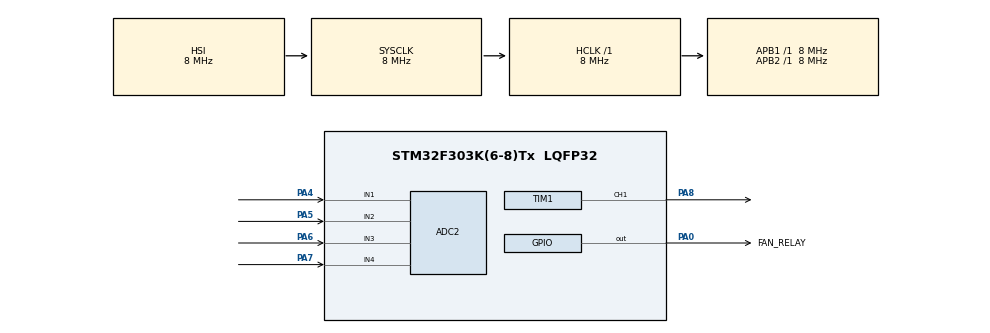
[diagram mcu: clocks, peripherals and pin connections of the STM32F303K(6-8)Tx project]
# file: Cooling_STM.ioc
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ADC2.Channel-0\#ChannelRegularConversion=ADC_CHANNEL_1
ADC2.Channel-1\#ChannelRegularConversion=ADC_CHANNEL_2
ADC2.Channel-2\#ChannelRegularConversion=ADC_CHANNEL_3
ADC2.Channel-3\#ChannelRegularConversion=ADC_CHANNEL_4
ADC2.NbrOfConversion=4
ADC2.NbrOfConversionFlag=1
ADC2.Offset-0\#ChannelRegularConversion=0
ADC2.Offset-1\#ChannelRegularConversion=0
ADC2.Offset-2\#ChannelRegularConversion=0
ADC2.Offset-3\#ChannelRegularConversion=0
ADC2.OffsetNumber-0\#ChannelRegularConversion=ADC_OFFSET_NONE
ADC2.OffsetNumber-1\#ChannelRegularConversion=ADC_OFFSET_NONE
ADC2.OffsetNumber-2\#ChannelRegularConversion=ADC_OFFSET_NONE
ADC2.OffsetNumber-3\#ChannelRegularConversion=ADC_OFFSET_NONE
ADC2.Rank-0\#ChannelRegularConversion=1
ADC2.Rank-1\#ChannelRegularConversion=2
ADC2.Rank-2\#ChannelRegularConversion=3
ADC2.Rank-3\#ChannelRegularConversion=4
ADC2.SamplingTime-0\#ChannelRegularConversion=ADC_SAMPLETIME_1CYCLE_5
ADC2.SamplingTime-1\#ChannelRegularConversion=ADC_SAMPLETIME_1CYCLE_5
ADC2.SamplingTime-2\#ChannelRegularConversion=ADC_SAMPLETIME_1CYCLE_5
ADC2.SamplingTime-3\#ChannelRegularConversion=ADC_SAMPLETIME_1CYCLE_5
ADC2.SamplingTimeOPAMP-1\#ChannelRegularConversion=ADC_SAMPLETIME_4CYCLES_5
ADC2.SamplingTimeOPAMP-2\#ChannelRegularConversion=ADC_SAMPLETIME_4CYCLES_5
ADC2.SamplingTimeOPAMP-3\#ChannelRegularConversion=ADC_SAMPLETIME_4CYCLES_5
Mcu.Family=STM32F3
Mcu.Name=STM32F303K(6-8)Tx
Mcu.Package=LQFP32
NVIC.PriorityGroup=NVIC_PRIORITYGROUP_4
PA0.GPIO_Label=FAN_RELAY
PA0.Signal=GPIO_Output
PA4.Mode=IN1-Single-Ended
PA4.Signal=ADC2_IN1
PA5.Mode=IN2-Single-Ended
PA5.Signal=ADC2_IN2
PA6.Mode=IN3-Single-Ended
PA6.Signal=ADC2_IN3
PA7.Mode=IN4-Single-Ended
PA7.Signal=ADC2_IN4
PA8.Signal=S_TIM1_CH1
ProjectManager.HeapSize=0x200
ProjectManager.StackSize=0x400
ProjectManager.TargetToolchain=STM32CubeIDE
RCC.AHBFreq_Value=8000000
RCC.APB1Freq_Value=8000000
RCC.APB2Freq_Value=8000000
RCC.CortexFreq_Value=8000000
RCC.HSE_VALUE=8000000
RCC.HSI_VALUE=8000000
RCC.PLLMUL=RCC_PLL_MUL4
RCC.SYSCLKFreq_VALUE=8000000
SH.S_TIM1_CH1.0=TIM1_CH1,PWM Generation1 CH1
TIM1.Channel-PWM\ Generation1\ CH1=TIM_CHANNEL_1
TIM1.Period=99
TIM1.Prescaler=79
TIM1.Pulse-PWM\ Generation1\ CH1=50
board=custom

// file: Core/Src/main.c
/* USER CODE BEGIN Header */
/**
  ******************************************************************************
  * @file           : main.c
  * @brief          : Main program body
  ******************************************************************************
  * @attention
  *
  * Copyright (c) 2026 STMicroelectronics.
  * All rights reserved.
  *
  * This software is licensed under terms that can be found in the LICENSE file
  * in the root directory of this software component.
  * If no LICENSE file comes with this software, it is provided AS-IS.
  *
  ******************************************************************************
  */
/* USER CODE END Header */
#include "main.h"

ADC_HandleTypeDef hadc2;

TIM_HandleTypeDef htim1;

void SystemClock_Config(void);
static void MX_GPIO_Init(void);
static void MX_ADC2_Init(void);
static void MX_TIM1_Init(void);

void Pump_SetDutyPercent(uint8_t percent)
{
    if (percent > 100) percent = 100;

    uint32_t period = __HAL_TIM_GET_AUTORELOAD(&htim1);
    uint32_t pulse = (period + 1) * percent / 100;

    __HAL_TIM_SET_COMPARE(&htim1, TIM_CHANNEL_1, pulse);
}

int main(void)
{

  /* MCU Configuration--------------------------------------------------------*/

  /* Reset of all peripherals, Initializes the Flash interface and the Systick. */
  HAL_Init();

  /* Configure the system clock */
  SystemClock_Config();

  /* Initialize all configured peripherals */
  MX_GPIO_Init();
  MX_ADC2_Init();
  MX_TIM1_Init();
  /* USER CODE BEGIN 2 */
  HAL_TIM_PWM_Start(&htim1, TIM_CHANNEL_1);
  __HAL_TIM_SET_COMPARE(&htim1, TIM_CHANNEL_1, (htim1.Init.Period + 1)/2); // for 50% duty

  /* USER CODE END 2 */

  /* Infinite loop */
  /* USER CODE BEGIN WHILE */
  while (1)
  {
	  HAL_ADC_Start(&hadc2);

	  // read temp1
	  HAL_ADC_PollForConversion(&hadc2, 100);
	  uint32_t adc_temp1 = HAL_ADC_GetValue(&hadc2);

	  // read temp2
	  HAL_ADC_PollForConversion(&hadc2, 100);
	  uint32_t adc_temp2 = HAL_ADC_GetValue(&hadc2);

	  // read pressure1
	  HAL_ADC_PollForConversion(&hadc2, 100);
	  uint32_t adc_press1 = HAL_ADC_GetValue(&hadc2);

	  // read pressure2
	  HAL_ADC_PollForConversion(&hadc2, 100);
	  uint32_t adc_press2 = HAL_ADC_GetValue(&hadc2);

	  HAL_ADC_Stop(&hadc2);

	  // TODO: replace after measuring real 70°F value
	  #define TEMP_ADC_THRESHOLD_70F 2000

	  uint8_t fan_on =
	      (adc_temp1 > TEMP_ADC_THRESHOLD_70F) ||
	      (adc_temp2 > TEMP_ADC_THRESHOLD_70F);

	  HAL_GPIO_WritePin(
	      FAN_RELAY_GPIO_Port,
	      FAN_RELAY_Pin,
	      fan_on ? GPIO_PIN_SET : GPIO_PIN_RESET
	  );

	  // pump fixed at 50%
	  Pump_SetDutyPercent(50);

	  HAL_Delay(250);
  }
  /* USER CODE END 3 */
}

void SystemClock_Config(void)
{
  RCC_OscInitTypeDef RCC_OscInitStruct = {0};
  RCC_ClkInitTypeDef RCC_ClkInitStruct = {0};
  RCC_PeriphCLKInitTypeDef PeriphClkInit = {0};

  /** Initializes the RCC Oscillators according to the specified parameters
  * in the RCC_OscInitTypeDef structure.
  */
  RCC_OscInitStruct.OscillatorType = RCC_OSCILLATORTYPE_HSI;
  RCC_OscInitStruct.HSIState = RCC_HSI_ON;
  RCC_OscInitStruct.HSICalibrationValue = RCC_HSICALIBRATION_DEFAULT;
  RCC_OscInitStruct.PLL.PLLState = RCC_PLL_ON;
  RCC_OscInitStruct.PLL.PLLSource = RCC_PLLSOURCE_HSI;
  RCC_OscInitStruct.PLL.PLLMUL = RCC_PLL_MUL4;
  if (HAL_RCC_OscConfig(&RCC_OscInitStruct) != HAL_OK)
  {
    Error_Handler();
  }

  /** Initializes the CPU, AHB and APB buses clocks
  */
  RCC_ClkInitStruct.ClockType = RCC_CLOCKTYPE_HCLK|RCC_CLOCKTYPE_SYSCLK
                              |RCC_CLOCKTYPE_PCLK1|RCC_CLOCKTYPE_PCLK2;
  RCC_ClkInitStruct.SYSCLKSource = RCC_SYSCLKSOURCE_HSI;
  RCC_ClkInitStruct.AHBCLKDivider = RCC_SYSCLK_DIV1;
  RCC_ClkInitStruct.APB1CLKDivider = RCC_HCLK_DIV1;
  RCC_ClkInitStruct.APB2CLKDivider = RCC_HCLK_DIV1;

  if (HAL_RCC_ClockConfig(&RCC_ClkInitStruct, FLASH_LATENCY_0) != HAL_OK)
  {
    Error_Handler();
  }
  PeriphClkInit.PeriphClockSelection = RCC_PERIPHCLK_TIM1|RCC_PERIPHCLK_ADC12;
  PeriphClkInit.Adc12ClockSelection = RCC_ADC12PLLCLK_DIV1;
  PeriphClkInit.Tim1ClockSelection = RCC_TIM1CLK_HCLK;
  if (HAL_RCCEx_PeriphCLKConfig(&PeriphClkInit) != HAL_OK)
  {
    Error_Handler();
  }
}

static void MX_ADC2_Init(void)
{

  ADC_ChannelConfTypeDef sConfig = {0};

  /** Common config
  */
  hadc2.Instance = ADC2;
  hadc2.Init.ClockPrescaler = ADC_CLOCK_ASYNC_DIV1;
  hadc2.Init.Resolution = ADC_RESOLUTION_12B;
  hadc2.Init.ScanConvMode = ADC_SCAN_ENABLE;
  hadc2.Init.ContinuousConvMode = DISABLE;
  hadc2.Init.DiscontinuousConvMode = DISABLE;
  hadc2.Init.ExternalTrigConvEdge = ADC_EXTERNALTRIGCONVEDGE_NONE;
  hadc2.Init.ExternalTrigConv = ADC_SOFTWARE_START;
  hadc2.Init.DataAlign = ADC_DATAALIGN_RIGHT;
  hadc2.Init.NbrOfConversion = 4;
  hadc2.Init.DMAContinuousRequests = DISABLE;
  hadc2.Init.EOCSelection = ADC_EOC_SINGLE_CONV;
  hadc2.Init.LowPowerAutoWait = DISABLE;
  hadc2.Init.Overrun = ADC_OVR_DATA_OVERWRITTEN;
  if (HAL_ADC_Init(&hadc2) != HAL_OK)
  {
    Error_Handler();
  }

  /** Configure Regular Channel
  */
  sConfig.Channel = ADC_CHANNEL_1;
  sConfig.Rank = ADC_REGULAR_RANK_1;
  sConfig.SingleDiff = ADC_SINGLE_ENDED;
  sConfig.SamplingTime = ADC_SAMPLETIME_1CYCLE_5;
  sConfig.OffsetNumber = ADC_OFFSET_NONE;
  sConfig.Offset = 0;
  if (HAL_ADC_ConfigChannel(&hadc2, &sConfig) != HAL_OK)
  {
    Error_Handler();
  }

  /** Configure Regular Channel
  */
  sConfig.Channel = ADC_CHANNEL_2;
  sConfig.Rank = ADC_REGULAR_RANK_2;
  if (HAL_ADC_ConfigChannel(&hadc2, &sConfig) != HAL_OK)
  {
    Error_Handler();
  }

  /** Configure Regular Channel
  */
  sConfig.Channel = ADC_CHANNEL_3;
  sConfig.Rank = ADC_REGULAR_RANK_3;
  if (HAL_ADC_ConfigChannel(&hadc2, &sConfig) != HAL_OK)
  {
    Error_Handler();
  }

  /** Configure Regular Channel
  */
  sConfig.Channel = ADC_CHANNEL_4;
  sConfig.Rank = ADC_REGULAR_RANK_4;
  if (HAL_ADC_ConfigChannel(&hadc2, &sConfig) != HAL_OK)
  {
    Error_Handler();
  }

}

static void MX_TIM1_Init(void)
{

  TIM_MasterConfigTypeDef sMasterConfig = {0};
  TIM_OC_InitTypeDef sConfigOC = {0};
  TIM_BreakDeadTimeConfigTypeDef sBreakDeadTimeConfig = {0};

  htim1.Instance = TIM1;
  htim1.Init.Prescaler = 79;
  htim1.Init.CounterMode = TIM_COUNTERMODE_UP;
  htim1.Init.Period = 99;
  htim1.Init.ClockDivision = TIM_CLOCKDIVISION_DIV1;
  htim1.Init.RepetitionCounter = 0;
  htim1.Init.AutoReloadPreload = TIM_AUTORELOAD_PRELOAD_DISABLE;
  if (HAL_TIM_PWM_Init(&htim1) != HAL_OK)
  {
    Error_Handler();
  }
  sMasterConfig.MasterOutputTrigger = TIM_TRGO_RESET;
  sMasterConfig.MasterOutputTrigger2 = TIM_TRGO2_RESET;
  sMasterConfig.MasterSlaveMode = TIM_MASTERSLAVEMODE_DISABLE;
  if (HAL_TIMEx_MasterConfigSynchronization(&htim1, &sMasterConfig) != HAL_OK)
  {
    Error_Handler();
  }
  sConfigOC.OCMode = TIM_OCMODE_PWM1;
  sConfigOC.Pulse = 50;
  sConfigOC.OCPolarity = TIM_OCPOLARITY_HIGH;
  sConfigOC.OCNPolarity = TIM_OCNPOLARITY_HIGH;
  sConfigOC.OCFastMode = TIM_OCFAST_DISABLE;
  sConfigOC.OCIdleState = TIM_OCIDLESTATE_RESET;
  sConfigOC.OCNIdleState = TIM_OCNIDLESTATE_RESET;
  if (HAL_TIM_PWM_ConfigChannel(&htim1, &sConfigOC, TIM_CHANNEL_1) != HAL_OK)
  {
    Error_Handler();
  }
  sBreakDeadTimeConfig.OffStateRunMode = TIM_OSSR_DISABLE;
  sBreakDeadTimeConfig.OffStateIDLEMode = TIM_OSSI_DISABLE;
  sBreakDeadTimeConfig.LockLevel = TIM_LOCKLEVEL_OFF;
  sBreakDeadTimeConfig.DeadTime = 0;
  sBreakDeadTimeConfig.BreakState = TIM_BREAK_DISABLE;
  sBreakDeadTimeConfig.BreakPolarity = TIM_BREAKPOLARITY_HIGH;
  sBreakDeadTimeConfig.BreakFilter = 0;
  sBreakDeadTimeConfig.Break2State = TIM_BREAK2_DISABLE;
  sBreakDeadTimeConfig.Break2Polarity = TIM_BREAK2POLARITY_HIGH;
  sBreakDeadTimeConfig.Break2Filter = 0;
  sBreakDeadTimeConfig.AutomaticOutput = TIM_AUTOMATICOUTPUT_DISABLE;
  if (HAL_TIMEx_ConfigBreakDeadTime(&htim1, &sBreakDeadTimeConfig) != HAL_OK)
  {
    Error_Handler();
  }
  HAL_TIM_MspPostInit(&htim1);

}

static void MX_GPIO_Init(void)
{
  GPIO_InitTypeDef GPIO_InitStruct = {0};

  /* GPIO Ports Clock Enable */
  __HAL_RCC_GPIOA_CLK_ENABLE();

  /*Configure GPIO pin Output Level */
  HAL_GPIO_WritePin(FAN_RELAY_GPIO_Port, FAN_RELAY_Pin, GPIO_PIN_RESET);

  /*Configure GPIO pin : FAN_RELAY_Pin */
  GPIO_InitStruct.Pin = FAN_RELAY_Pin;
  GPIO_InitStruct.Mode = GPIO_MODE_OUTPUT_PP;
  GPIO_InitStruct.Pull = GPIO_NOPULL;
  GPIO_InitStruct.Speed = GPIO_SPEED_FREQ_LOW;
  HAL_GPIO_Init(FAN_RELAY_GPIO_Port, &GPIO_InitStruct);

}

void Error_Handler(void)
{
  __disable_irq();
  while (1)
  {
  }
}
